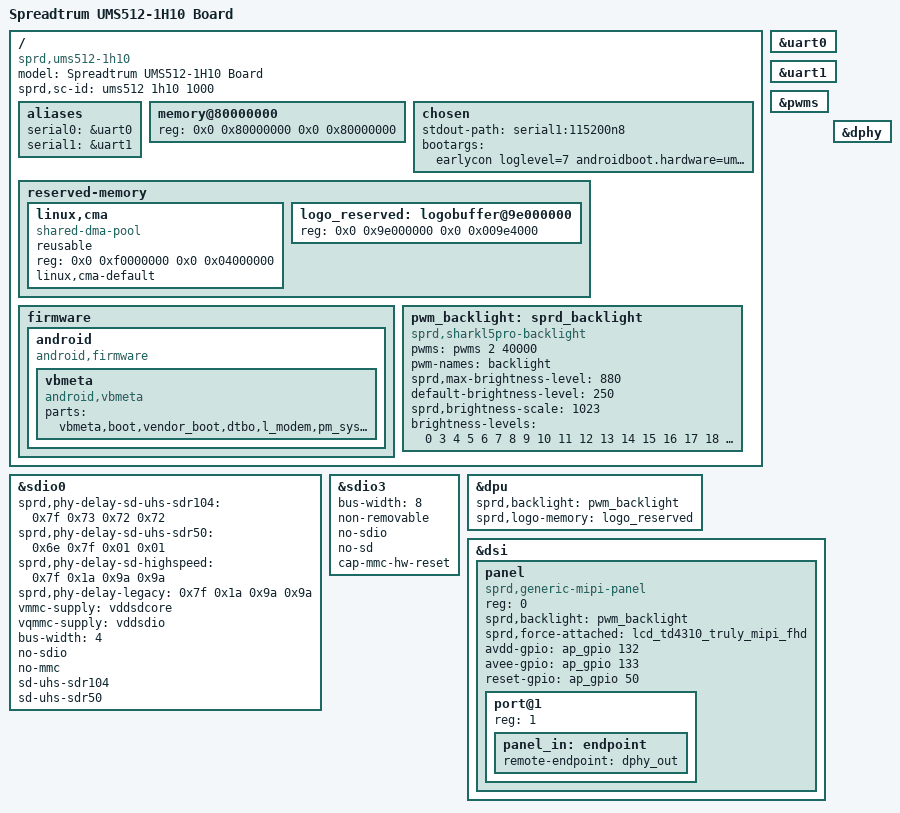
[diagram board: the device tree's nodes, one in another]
// SPDX-License-Identifier: GPL-2.0-only
/*
 * Unisoc UMS512-1h10 boards DTS file
 *
 * Copyright (C) 2021, Unisoc Inc.
 */

/dts-v1/;

#include <dt-bindings/gpio/gpio.h>
#include "ums512.dtsi"
#include "sc2730.dtsi"
#include "lcd/lcd_td4310_truly_mipi_fhd.dtsi"

/ {
	model = "Spreadtrum UMS512-1H10 Board";

	compatible = "sprd,ums512-1h10", "sprd,ums512";

	sprd,sc-id = "ums512 1h10 1000";

	aliases {
		serial0 = &uart0;
		serial1 = &uart1;
	};

	memory@80000000 {
		device_type = "memory";
		reg = <0x0 0x80000000 0x0 0x80000000>;
	};

	chosen {
		stdout-path = "serial1:115200n8";
		bootargs = "earlycon loglevel=7 androidboot.hardware=ums512 printk.devkmsg=on  androidboot.selinux=permissive androidboot.boot_devices=soc/soc:ap-apb/71400000.sdio dummy_hcd.num=0 swiotlb=1 initcall_debug=1 lcd_name=lcd_td4310_truly_mipi_fhd ";
	};

	reserved-memory {
		#address-cells = <2>;
		#size-cells = <2>;
		ranges;

		/* global autoconfigured region for contiguous allocations */
		linux,cma {
			compatible = "shared-dma-pool";
			reusable;
			reg = <0x0 0xf0000000 0x0 0x04000000>;
			linux,cma-default;
		};
		logo_reserved: logobuffer@9e000000{
			reg = <0x0 0x9e000000 0x0 0x009e4000>;
		};
	};
	firmware {
		android {
			compatible = "android,firmware";
			vbmeta {
				compatible = "android,vbmeta";
				parts = "vbmeta,boot,vendor_boot,dtbo,l_modem,pm_sys,l_ldsp,l_gdsp,l_agdsp,l_cdsp";
			};
		};
	};

	pwm_backlight: sprd_backlight {
		compatible = "sprd,sharkl5pro-backlight";
		pwms = <&pwms 2 40000>;
		pwm-names = "backlight";
		sprd,max-brightness-level = <880>;
		default-brightness-level = <250>;
		sprd,brightness-scale = <1023>;
		brightness-levels = <
					  0   3   4   5   6   7
			  8   9  10  11  12  13  14  15  16  17
			 18  19  20  21  22  23  24  25  26  27
			 28  29  31  33  35  37  39  41  43  45
			 46  48  50  52  54  56  58  60  62  64
			 66  68  70  72  74  76  78  80  82  84
			 86  88  90  92  94  96  98 100 102 104
			106 108 110 112 114 116 118 120 122 124
			126 128 130 132 134 136 138 140 142 144
			146 148 150 152 154 156 158 160 162 164
			166 169 172 175 178 181 184 187 190 193
			196 199 202 205 208 211 214 217 220 223
			226 229 232 235 238 241 244 247 250 253
			256 259 262 265 268 271 274 277 280 283
			286 290 294 298 302 306 310 314 318 322
			326 330 334 338 342 346 350 354 358 362
			366 370 374 378 382 386 390 394 398 402
			406 410 414 418 422 426 430 434 438 442
			446 451 456 461 466 471 476 481 486 491
			496 501 506 511 516 521 526 531 536 541
			546 551 556 561 566 571 576 581 586 591
			596 601 606 611 616 621 626 631 636 641
			646 652 658 664 670 676 682 688 694 700
			706 712 718 724 730 736 742 748 754 760
			766 772 778 784 790 796 802 808 814 820
			826 832 838 844 850 856 862 868 874 880
			>;
	};
	firmware {
		android {
			compatible = "android,firmware";
			vbmeta {
				compatible = "android,vbmeta";
				parts = "vbmeta,boot,vendor_boot,dtbo,l_modem,pm_sys,l_ldsp,l_gdsp,l_agdsp,l_cdsp";
			};
		};
	};
};

&uart0 {
	status = "okay";
};

&uart1 {
	status = "okay";
};

&sdio0 {
	//cd-gpios = <&eic_sync 19 GPIO_ACTIVE_HIGH>;
	sprd,phy-delay-sd-uhs-sdr104 = <0x7f 0x73 0x72 0x72>;
	sprd,phy-delay-sd-uhs-sdr50 = <0x6e 0x7f 0x01 0x01>;
	sprd,phy-delay-sd-highspeed = <0x7f 0x1a 0x9a 0x9a>;
	sprd,phy-delay-legacy = <0x7f 0x1a 0x9a 0x9a>;
	vmmc-supply = <&vddsdcore>;
	vqmmc-supply = <&vddsdio>;
	bus-width = <4>;
	no-sdio;
	no-mmc;
	sd-uhs-sdr104;
	sd-uhs-sdr50;
	status = "okay";
};

&sdio3 {
	bus-width = <8>;
	non-removable;
	no-sdio;
	no-sd;
	cap-mmc-hw-reset;
	status = "okay";
};

&pwms {
	status = "okay";
};

&dpu {
	sprd,backlight = <&pwm_backlight>;
	sprd,logo-memory = <&logo_reserved>;
	status = "okay";
};

&dsi {
	status = "okay";
	#address-cells = <1>;
	#size-cells = <0>;

	panel: panel {
		compatible = "sprd,generic-mipi-panel";
		#address-cells = <1>;
		#size-cells = <0>;
		reg = <0>;

		sprd,backlight = <&pwm_backlight>;
		sprd,force-attached = "lcd_td4310_truly_mipi_fhd";

		avdd-gpio = <&ap_gpio 132 GPIO_ACTIVE_HIGH>;
		avee-gpio = <&ap_gpio 133 GPIO_ACTIVE_HIGH>;
		reset-gpio = <&ap_gpio 50 GPIO_ACTIVE_HIGH>;
		port@1 {
			reg = <1>;
			panel_in: endpoint {
				remote-endpoint = <&dphy_out>;
			};
		};
	};
};

&dphy {
	status = "okay";
};

